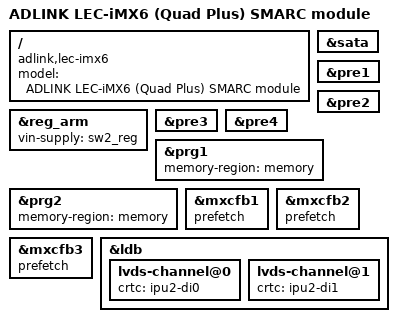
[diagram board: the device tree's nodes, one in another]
// SPDX-License-Identifier: GPL-2.0+ OR MIT
//
// Copyright 2014-2016 LiPPERT ADLINK Technology GmbH
// Copyright 2016 Freescale Semiconductor, Inc.

/dts-v1/;

#include "imx6qp.dtsi"
#include "lec-imx6.dtsi"

/ {
	model = "ADLINK LEC-iMX6 (Quad Plus) SMARC module";
	compatible = "adlink,lec-imx6", "fsl,imx6qp";
};

&reg_arm {
	vin-supply = <&sw2_reg>;
};

&sata {
	status = "okay";
};

&pre1 {
	status = "okay";
};

&pre2 {
	status = "okay";
};

&pre3 {
	status = "okay";
};

&pre4 {
	status = "okay";
};

&prg1 {
	memory-region = <&memory>;
	status = "okay";
};

&prg2 {
	memory-region = <&memory>;
	status = "okay";
};

&mxcfb1 {
	prefetch;
	status = "okay";
};

&mxcfb2 {
	prefetch;
	status = "okay";
};

&mxcfb3 {
	prefetch;
	status = "okay";
};

&ldb {
	lvds-channel@0 {
		crtc = "ipu2-di0";
	};

	lvds-channel@1 {
		crtc = "ipu2-di1";
	};
};
